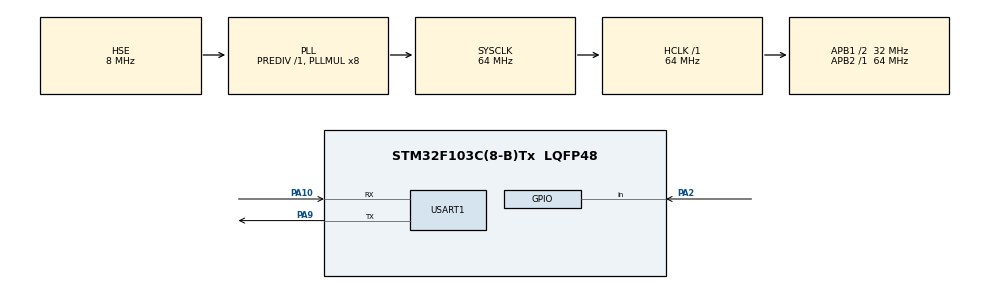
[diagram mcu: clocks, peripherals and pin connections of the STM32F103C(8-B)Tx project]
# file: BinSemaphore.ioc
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FREERTOS.BinarySemaphores01=BinSem,Dynamic,NULL
FREERTOS.Tasks01=NormalTask,0,128,StartNormalTask,Default,NULL,Dynamic,NULL,NULL;HighTask,1,128,StartHighTask,Default,NULL,Dynamic,NULL,NULL;LowTask,-1,128,StartLowTask,Default,NULL,Dynamic,NULL,NULL
FREERTOS.configUSE_NEWLIB_REENTRANT=1
Mcu.Family=STM32F1
Mcu.Name=STM32F103C(8-B)Tx
Mcu.Package=LQFP48
NVIC.PriorityGroup=NVIC_PRIORITYGROUP_4
NVIC.TIM4_IRQn=true\:15\:0\:false\:false\:true\:false\:false\:true\:true
NVIC.TimeBase=TIM4_IRQn
NVIC.TimeBaseIP=TIM4
PA10.Mode=Asynchronous
PA10.Signal=USART1_RX
PA13.Mode=Serial_Wire
PA13.Signal=SYS_JTMS-SWDIO
PA14.Mode=Serial_Wire
PA14.Signal=SYS_JTCK-SWCLK
PA2.GPIO_PuPd=GPIO_NOPULL
PA2.Signal=GPIO_Input
PA9.Mode=Asynchronous
PA9.Signal=USART1_TX
PD0-OSC_IN.Mode=HSE-External-Oscillator
PD0-OSC_IN.Signal=RCC_OSC_IN
PD1-OSC_OUT.Mode=HSE-External-Oscillator
PD1-OSC_OUT.Signal=RCC_OSC_OUT
ProjectManager.HeapSize=0x200
ProjectManager.StackSize=0x400
ProjectManager.TargetToolchain=STM32CubeIDE
RCC.AHBFreq_Value=64000000
RCC.APB1CLKDivider=RCC_HCLK_DIV2
RCC.APB1Freq_Value=32000000
RCC.APB1TimFreq_Value=64000000
RCC.APB2Freq_Value=64000000
RCC.APB2TimFreq_Value=64000000
RCC.HCLKFreq_Value=64000000
RCC.PLLMUL=RCC_PLL_MUL8
RCC.PLLSourceVirtual=RCC_PLLSOURCE_HSE
RCC.SYSCLKFreq_VALUE=64000000
RCC.SYSCLKSource=RCC_SYSCLKSOURCE_PLLCLK
RCC.USBFreq_Value=64000000
TIM1.Prescaler=63
USART1.VirtualMode=VM_ASYNC
VP_FREERTOS_VS_CMSIS_V1.Mode=CMSIS_V1
VP_SYS_VS_tim4.Mode=TIM4
VP_TIM1_VS_ClockSourceINT.Mode=Internal
board=custom

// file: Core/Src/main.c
/* USER CODE BEGIN Header */
/**
  ******************************************************************************
  * @file           : main.c
  * @brief          : Main program body
  ******************************************************************************
  * @attention
  *
  * Copyright (c) 2025 STMicroelectronics.
  * All rights reserved.
  *
  * This software is licensed under terms that can be found in the LICENSE file
  * in the root directory of this software component.
  * If no LICENSE file comes with this software, it is provided AS-IS.
  *
  ******************************************************************************
  */
/* USER CODE END Header */
#include "main.h"
#include "cmsis_os.h"

/* USER CODE BEGIN Includes */
#include "string.h"
#include "stdio.h"
/* USER CODE END Includes */

 TIM_HandleTypeDef htim1;

UART_HandleTypeDef huart1;

osThreadId NormalTaskHandle;
osThreadId HighTaskHandle;
osThreadId LowTaskHandle;
osSemaphoreId BinSemHandle;

void SystemClock_Config(void);
static void MX_GPIO_Init(void);
static void MX_TIM1_Init(void);
static void MX_USART1_UART_Init(void);
void StartNormalTask(void const * argument);
void StartHighTask(void const * argument);
void StartLowTask(void const * argument);

int main(void)
{

  /* MCU Configuration--------------------------------------------------------*/

  /* Reset of all peripherals, Initializes the Flash interface and the Systick. */
  HAL_Init();

  /* Configure the system clock */
  SystemClock_Config();

  /* Initialize all configured peripherals */
  MX_GPIO_Init();
  MX_TIM1_Init();
  MX_USART1_UART_Init();

  /* Create the semaphores(s) */
  /* definition and creation of BinSem */
  osSemaphoreDef(BinSem);
  BinSemHandle = osSemaphoreCreate(osSemaphore(BinSem), 1);

  /* Create the thread(s) */
  /* definition and creation of NormalTask */
  osThreadDef(NormalTask, StartNormalTask, osPriorityNormal, 0, 128);
  NormalTaskHandle = osThreadCreate(osThread(NormalTask), NULL);

  /* definition and creation of HighTask */
  osThreadDef(HighTask, StartHighTask, osPriorityAboveNormal, 0, 128);
  HighTaskHandle = osThreadCreate(osThread(HighTask), NULL);

  /* definition and creation of LowTask */
  osThreadDef(LowTask, StartLowTask, osPriorityBelowNormal, 0, 128);
  LowTaskHandle = osThreadCreate(osThread(LowTask), NULL);

  /* Start scheduler */
  osKernelStart();

  /* We should never get here as control is now taken by the scheduler */
  /* Infinite loop */
  while (1)
  {

  }
}

void SystemClock_Config(void)
{
  RCC_OscInitTypeDef RCC_OscInitStruct = {0};
  RCC_ClkInitTypeDef RCC_ClkInitStruct = {0};

  /** Initializes the RCC Oscillators according to the specified parameters
  * in the RCC_OscInitTypeDef structure.
  */
  RCC_OscInitStruct.OscillatorType = RCC_OSCILLATORTYPE_HSE;
  RCC_OscInitStruct.HSEState = RCC_HSE_ON;
  RCC_OscInitStruct.HSEPredivValue = RCC_HSE_PREDIV_DIV1;
  RCC_OscInitStruct.HSIState = RCC_HSI_ON;
  RCC_OscInitStruct.PLL.PLLState = RCC_PLL_ON;
  RCC_OscInitStruct.PLL.PLLSource = RCC_PLLSOURCE_HSE;
  RCC_OscInitStruct.PLL.PLLMUL = RCC_PLL_MUL8;
  if (HAL_RCC_OscConfig(&RCC_OscInitStruct) != HAL_OK)
  {
    Error_Handler();
  }

  /** Initializes the CPU, AHB and APB buses clocks
  */
  RCC_ClkInitStruct.ClockType = RCC_CLOCKTYPE_HCLK|RCC_CLOCKTYPE_SYSCLK
                              |RCC_CLOCKTYPE_PCLK1|RCC_CLOCKTYPE_PCLK2;
  RCC_ClkInitStruct.SYSCLKSource = RCC_SYSCLKSOURCE_PLLCLK;
  RCC_ClkInitStruct.AHBCLKDivider = RCC_SYSCLK_DIV1;
  RCC_ClkInitStruct.APB1CLKDivider = RCC_HCLK_DIV2;
  RCC_ClkInitStruct.APB2CLKDivider = RCC_HCLK_DIV1;

  if (HAL_RCC_ClockConfig(&RCC_ClkInitStruct, FLASH_LATENCY_2) != HAL_OK)
  {
    Error_Handler();
  }
}

static void MX_TIM1_Init(void)
{

  TIM_ClockConfigTypeDef sClockSourceConfig = {0};
  TIM_MasterConfigTypeDef sMasterConfig = {0};

  htim1.Instance = TIM1;
  htim1.Init.Prescaler = 63;
  htim1.Init.CounterMode = TIM_COUNTERMODE_UP;
  htim1.Init.Period = 65535;
  htim1.Init.ClockDivision = TIM_CLOCKDIVISION_DIV1;
  htim1.Init.RepetitionCounter = 0;
  htim1.Init.AutoReloadPreload = TIM_AUTORELOAD_PRELOAD_DISABLE;
  if (HAL_TIM_Base_Init(&htim1) != HAL_OK)
  {
    Error_Handler();
  }
  sClockSourceConfig.ClockSource = TIM_CLOCKSOURCE_INTERNAL;
  if (HAL_TIM_ConfigClockSource(&htim1, &sClockSourceConfig) != HAL_OK)
  {
    Error_Handler();
  }
  sMasterConfig.MasterOutputTrigger = TIM_TRGO_RESET;
  sMasterConfig.MasterSlaveMode = TIM_MASTERSLAVEMODE_DISABLE;
  if (HAL_TIMEx_MasterConfigSynchronization(&htim1, &sMasterConfig) != HAL_OK)
  {
    Error_Handler();
  }

}

static void MX_USART1_UART_Init(void)
{

  huart1.Instance = USART1;
  huart1.Init.BaudRate = 115200;
  huart1.Init.WordLength = UART_WORDLENGTH_8B;
  huart1.Init.StopBits = UART_STOPBITS_1;
  huart1.Init.Parity = UART_PARITY_NONE;
  huart1.Init.Mode = UART_MODE_TX_RX;
  huart1.Init.HwFlowCtl = UART_HWCONTROL_NONE;
  huart1.Init.OverSampling = UART_OVERSAMPLING_16;
  if (HAL_UART_Init(&huart1) != HAL_OK)
  {
    Error_Handler();
  }

}

static void MX_GPIO_Init(void)
{
  GPIO_InitTypeDef GPIO_InitStruct = {0};

  /* GPIO Ports Clock Enable */
  __HAL_RCC_GPIOD_CLK_ENABLE();
  __HAL_RCC_GPIOA_CLK_ENABLE();

  /*Configure GPIO pin : PA2 */
  GPIO_InitStruct.Pin = GPIO_PIN_2;
  GPIO_InitStruct.Mode = GPIO_MODE_INPUT;
  GPIO_InitStruct.Pull = GPIO_NOPULL;
  HAL_GPIO_Init(GPIOA, &GPIO_InitStruct);

}

void StartNormalTask(void const * argument)
{
  /* USER CODE BEGIN 5 */
  /* Infinite loop */
  for(;;)
  {
	  char *str1 = "Entered Medium Task\n";
	  HAL_UART_Transmit(&huart1, (uint8_t *) str1, strlen (str1), 100);

	  char *str2 = "Leaving Medium Task\n\n";
	  HAL_UART_Transmit(&huart1, (uint8_t *) str2, strlen (str2), 100);
	  osDelay(500);

  }
  /* USER CODE END 5 */
}

void StartHighTask(void const * argument)
{
  /* USER CODE BEGIN StartHighTask */
  /* Infinite loop */
  for(;;)
  {
	  char *str1 = "Entered HighTask and waiting for Semaphore\n";
	  HAL_UART_Transmit(&huart1, (uint8_t *) str1, strlen (str1), 100);

	  osSemaphoreWait(BinSemHandle, osWaitForever);

	  char *str3 = "Semaphore acquired by HIGH Task\n";
	  HAL_UART_Transmit(&huart1, (uint8_t *) str3, strlen (str3), 100);

	  char *str2 = "Leaving HighTask and releasing Semaphore\n\n";
	  HAL_UART_Transmit(&huart1, (uint8_t *) str2, strlen (str2), 100);

	  osSemaphoreRelease(BinSemHandle);
	  osDelay(500);
  }
  /* USER CODE END StartHighTask */
}

void StartLowTask(void const * argument)
{
  /* USER CODE BEGIN StartLowTask */
  /* Infinite loop */
  for(;;)
  {
	  char *str1 = "Entered LOWTask and waiting for semaphore\n";
	  HAL_UART_Transmit(&huart1, (uint8_t *) str1, strlen (str1), 100);

	  osSemaphoreWait(BinSemHandle, osWaitForever);
	  char *str3 = "Semaphore acquired by LOW Task\n";
	  HAL_UART_Transmit(&huart1, (uint8_t *) str3, strlen (str3), 100);

	  while (HAL_GPIO_ReadPin(GPIOA, GPIO_PIN_2));  // wait till the button connect with PA2 the pin go low

	  char *str2 = "Leaving LOWTask and releasing Semaphore\n\n";
	  HAL_UART_Transmit(&huart1, (uint8_t *) str2, strlen (str2), 100);

	  osSemaphoreRelease(BinSemHandle);
	  osDelay(500);
  }
  /* USER CODE END StartLowTask */
}

void HAL_TIM_PeriodElapsedCallback(TIM_HandleTypeDef *htim)
{
  if (htim->Instance == TIM4) {
    HAL_IncTick();
  }
}

void Error_Handler(void)
{
  __disable_irq();
  while (1)
  {
  }
}
